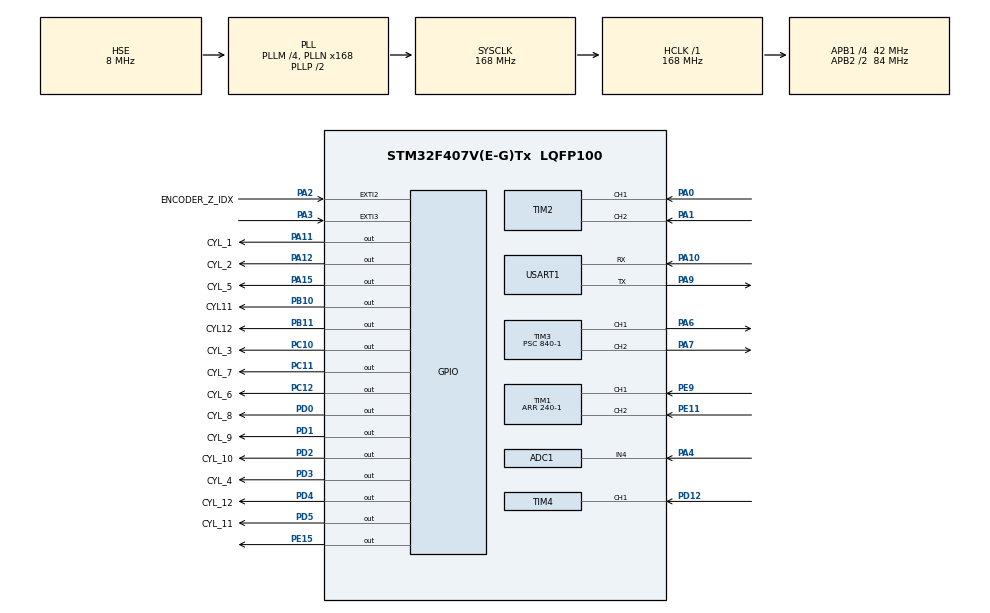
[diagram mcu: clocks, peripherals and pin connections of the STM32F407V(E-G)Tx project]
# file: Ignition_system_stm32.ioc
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ADC1.Channel-0\#ChannelRegularConversion=ADC_CHANNEL_4
ADC1.NbrOfConversionFlag=1
ADC1.Rank-0\#ChannelRegularConversion=1
ADC1.SamplingTime-0\#ChannelRegularConversion=ADC_SAMPLETIME_3CYCLES
ADC1.master=1
Mcu.Family=STM32F4
Mcu.Name=STM32F407V(E-G)Tx
Mcu.Package=LQFP100
NVIC.EXTI2_IRQn=true\:0\:0\:false\:false\:true\:true\:true\:true
NVIC.EXTI3_IRQn=true\:0\:0\:false\:false\:true\:true\:true\:true
NVIC.PriorityGroup=NVIC_PRIORITYGROUP_4
NVIC.TIM1_UP_TIM10_IRQn=true\:0\:0\:false\:false\:true\:true\:true\:true
NVIC.TIM4_IRQn=true\:0\:0\:false\:false\:true\:true\:true\:true
PA0-WKUP.Signal=S_TIM2_CH1_ETR
PA1.Signal=S_TIM2_CH2
PA10.Mode=Asynchronous
PA10.Signal=USART1_RX
PA11.GPIO_Label=CYL_1
PA11.GPIO_Speed=GPIO_SPEED_FREQ_VERY_HIGH
PA11.Signal=GPIO_Output
PA12.GPIO_Label=CYL_2
PA12.GPIO_Speed=GPIO_SPEED_FREQ_VERY_HIGH
PA12.Signal=GPIO_Output
PA13.Mode=Serial_Wire
PA13.Signal=SYS_JTMS-SWDIO
PA14.Mode=Serial_Wire
PA14.Signal=SYS_JTCK-SWCLK
PA15.GPIO_Label=CYL_5
PA15.GPIO_Speed=GPIO_SPEED_FREQ_VERY_HIGH
PA15.Signal=GPIO_Output
PA2.GPIO_Label=ENCODER_Z_IDX
PA2.GPIO_ModeDefaultEXTI=GPIO_MODE_IT_RISING
PA2.GPIO_PuPd=GPIO_NOPULL
PA2.Signal=GPXTI2
PA3.Signal=GPXTI3
PA4.Signal=ADCx_IN4
PA6.Signal=S_TIM3_CH1
PA7.Signal=S_TIM3_CH2
PA9.Mode=Asynchronous
PA9.Signal=USART1_TX
PB10.GPIO_Label=CYL11
PB10.GPIO_Speed=GPIO_SPEED_FREQ_VERY_HIGH
PB10.Signal=GPIO_Output
PB11.GPIO_Label=CYL12
PB11.GPIO_Speed=GPIO_SPEED_FREQ_VERY_HIGH
PB11.Signal=GPIO_Output
PC10.GPIO_Label=CYL_3
PC10.GPIO_Speed=GPIO_SPEED_FREQ_VERY_HIGH
PC10.Signal=GPIO_Output
PC11.GPIO_Label=CYL_7
PC11.GPIO_Speed=GPIO_SPEED_FREQ_VERY_HIGH
PC11.Signal=GPIO_Output
PC12.GPIO_Label=CYL_6
PC12.GPIO_Speed=GPIO_SPEED_FREQ_VERY_HIGH
PC12.Signal=GPIO_Output
PC14-OSC32_IN.Mode=LSE-External-Oscillator
PC14-OSC32_IN.Signal=RCC_OSC32_IN
PC15-OSC32_OUT.Mode=LSE-External-Oscillator
PC15-OSC32_OUT.Signal=RCC_OSC32_OUT
PD0.GPIO_Label=CYL_8
PD0.GPIO_Speed=GPIO_SPEED_FREQ_VERY_HIGH
PD0.Signal=GPIO_Output
PD1.GPIO_Label=CYL_9
PD1.GPIO_Speed=GPIO_SPEED_FREQ_VERY_HIGH
PD1.Signal=GPIO_Output
PD12.Signal=S_TIM4_CH1
PD2.GPIO_Label=CYL_10
PD2.GPIO_Speed=GPIO_SPEED_FREQ_VERY_HIGH
PD2.Signal=GPIO_Output
PD3.GPIO_Label=CYL_4
PD3.GPIO_Speed=GPIO_SPEED_FREQ_VERY_HIGH
PD3.Signal=GPIO_Output
PD4.GPIO_Label=CYL_12
PD4.GPIO_Speed=GPIO_SPEED_FREQ_VERY_HIGH
PD4.Signal=GPIO_Output
PD5.GPIO_Label=CYL_11
PD5.GPIO_Speed=GPIO_SPEED_FREQ_VERY_HIGH
PD5.Signal=GPIO_Output
PE11.Signal=S_TIM1_CH2
PE15.Signal=GPIO_Output
PE9.Signal=S_TIM1_CH1
PH0-OSC_IN.Mode=HSE-External-Oscillator
PH0-OSC_IN.Signal=RCC_OSC_IN
PH1-OSC_OUT.Mode=HSE-External-Oscillator
PH1-OSC_OUT.Signal=RCC_OSC_OUT
ProjectManager.HeapSize=0x200
ProjectManager.StackSize=0x400
ProjectManager.TargetToolchain=STM32CubeIDE
RCC.48MHZClocksFreq_Value=84000000
RCC.AHBFreq_Value=168000000
RCC.APB1CLKDivider=RCC_HCLK_DIV4
RCC.APB1Freq_Value=42000000
RCC.APB1TimFreq_Value=84000000
RCC.APB2CLKDivider=RCC_HCLK_DIV2
RCC.APB2Freq_Value=84000000
RCC.APB2TimFreq_Value=168000000
RCC.CortexFreq_Value=168000000
RCC.HCLKFreq_Value=168000000
RCC.HSE_VALUE=8000000
RCC.HSI_VALUE=16000000
RCC.PLLM=4
RCC.PLLN=168
RCC.PLLSourceVirtual=RCC_PLLSOURCE_HSE
RCC.SYSCLKFreq_VALUE=168000000
RCC.SYSCLKSource=RCC_SYSCLKSOURCE_PLLCLK
RCC.VCOOutputFreq_Value=336000000
SH.ADCx_IN4.0=ADC1_IN4,IN4
SH.S_TIM1_CH1.0=TIM1_CH1,Encoder_Interface
SH.S_TIM1_CH2.0=TIM1_CH2,Encoder_Interface
SH.S_TIM2_CH1_ETR.0=TIM2_CH1,Encoder_Interface
SH.S_TIM2_CH2.0=TIM2_CH2,Encoder_Interface
SH.S_TIM3_CH1.0=TIM3_CH1,PWM Generation1 CH1
SH.S_TIM3_CH2.0=TIM3_CH2,PWM Generation2 CH2
SH.S_TIM4_CH1.0=TIM4_CH1,Input_Capture1_from_TI1
TIM1.EncoderMode=TIM_ENCODERMODE_TI12
TIM1.IC1Polarity=TIM_ICPOLARITY_FALLING
TIM1.IC2Polarity=TIM_ICPOLARITY_FALLING
TIM1.Period=240-1
TIM2.EncoderMode=TIM_ENCODERMODE_TI12
TIM2.IC1Polarity=TIM_ICPOLARITY_FALLING
TIM2.IC2Polarity=TIM_ICPOLARITY_FALLING
TIM3.AutoReloadPreload=TIM_AUTORELOAD_PRELOAD_ENABLE
TIM3.Channel-PWM\ Generation1\ CH1=TIM_CHANNEL_1
TIM3.Channel-PWM\ Generation2\ CH2=TIM_CHANNEL_2
TIM3.Period=10000-1
TIM3.Prescaler=840-1
TIM4.Channel-Input_Capture1_from_TI1=TIM_CHANNEL_1
TIM4.ICPolarity_CH1=TIM_INPUTCHANNELPOLARITY_FALLING
TIM4.Prescaler=0
TIM5.Prescaler=84-1
USART1.VirtualMode=VM_ASYNC
VP_TIM3_VS_ClockSourceINT.Mode=Internal
VP_TIM4_VS_ClockSourceINT.Mode=Internal
VP_TIM5_VS_ClockSourceINT.Mode=Internal
VP_TIM8_VS_ClockSourceINT.Mode=Internal
board=custom

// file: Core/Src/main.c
/* USER CODE BEGIN Header */
/**
  ******************************************************************************
  * @file           : main.c
  * @brief          : Main program body
  ******************************************************************************
  * @attention
  *
  * Copyright (c) 2024 STMicroelectronics.
  * All rights reserved.
  *
  * This software is licensed under terms that can be found in the LICENSE file
  * in the root directory of this software component.
  * If no LICENSE file comes with this software, it is provided AS-IS.
  *
  ******************************************************************************
  */
/* USER CODE END Header */
#include "main.h"

/* USER CODE BEGIN Includes */
#include "submain.h"
#include "string.h"
/* USER CODE END Includes */

ADC_HandleTypeDef hadc1;

TIM_HandleTypeDef htim1;
TIM_HandleTypeDef htim2;
TIM_HandleTypeDef htim3;
TIM_HandleTypeDef htim4;
TIM_HandleTypeDef htim5;
TIM_HandleTypeDef htim8;

UART_HandleTypeDef huart1;

void SystemClock_Config(void);
static void MX_GPIO_Init(void);
static void MX_USART1_UART_Init(void);
static void MX_TIM2_Init(void);
static void MX_TIM1_Init(void);
static void MX_TIM4_Init(void);
static void MX_TIM3_Init(void);
static void MX_TIM5_Init(void);
static void MX_TIM8_Init(void);
static void MX_ADC1_Init(void);

int main(void)
{
  /* USER CODE BEGIN 1 */
/* uint8_t buf[12]; */
  /* USER CODE END 1 */

  /* MCU Configuration--------------------------------------------------------*/

  /* Reset of all peripherals, Initializes the Flash interface and the Systick. */
  HAL_Init();

  /* Configure the system clock */
  SystemClock_Config();

  /* Initialize all configured peripherals */
  MX_GPIO_Init();
  MX_USART1_UART_Init();
  MX_TIM2_Init();
  MX_TIM1_Init();
  MX_TIM4_Init();
  MX_TIM3_Init();
  MX_TIM5_Init();
  MX_TIM8_Init();
  MX_ADC1_Init();
  /* USER CODE BEGIN 2 */

  init();

  /* USER CODE END 2 */

  /* Infinite loop */
  /* USER CODE BEGIN WHILE */
  while (1)
  {
	  loop();

    /* USER CODE END WHILE */

  }
}

void SystemClock_Config(void)
{
  RCC_OscInitTypeDef RCC_OscInitStruct = {0};
  RCC_ClkInitTypeDef RCC_ClkInitStruct = {0};

  /** Configure the main internal regulator output voltage
  */
  __HAL_RCC_PWR_CLK_ENABLE();
  __HAL_PWR_VOLTAGESCALING_CONFIG(PWR_REGULATOR_VOLTAGE_SCALE1);

  /** Initializes the RCC Oscillators according to the specified parameters
  * in the RCC_OscInitTypeDef structure.
  */
  RCC_OscInitStruct.OscillatorType = RCC_OSCILLATORTYPE_HSE;
  RCC_OscInitStruct.HSEState = RCC_HSE_ON;
  RCC_OscInitStruct.PLL.PLLState = RCC_PLL_ON;
  RCC_OscInitStruct.PLL.PLLSource = RCC_PLLSOURCE_HSE;
  RCC_OscInitStruct.PLL.PLLM = 4;
  RCC_OscInitStruct.PLL.PLLN = 168;
  RCC_OscInitStruct.PLL.PLLP = RCC_PLLP_DIV2;
  RCC_OscInitStruct.PLL.PLLQ = 4;
  if (HAL_RCC_OscConfig(&RCC_OscInitStruct) != HAL_OK)
  {
    Error_Handler();
  }

  /** Initializes the CPU, AHB and APB buses clocks
  */
  RCC_ClkInitStruct.ClockType = RCC_CLOCKTYPE_HCLK|RCC_CLOCKTYPE_SYSCLK
                              |RCC_CLOCKTYPE_PCLK1|RCC_CLOCKTYPE_PCLK2;
  RCC_ClkInitStruct.SYSCLKSource = RCC_SYSCLKSOURCE_PLLCLK;
  RCC_ClkInitStruct.AHBCLKDivider = RCC_SYSCLK_DIV1;
  RCC_ClkInitStruct.APB1CLKDivider = RCC_HCLK_DIV4;
  RCC_ClkInitStruct.APB2CLKDivider = RCC_HCLK_DIV2;

  if (HAL_RCC_ClockConfig(&RCC_ClkInitStruct, FLASH_LATENCY_5) != HAL_OK)
  {
    Error_Handler();
  }
}

static void MX_ADC1_Init(void)
{

  ADC_ChannelConfTypeDef sConfig = {0};

  /** Configure the global features of the ADC (Clock, Resolution, Data Alignment and number of conversion)
  */
  hadc1.Instance = ADC1;
  hadc1.Init.ClockPrescaler = ADC_CLOCK_SYNC_PCLK_DIV4;
  hadc1.Init.Resolution = ADC_RESOLUTION_12B;
  hadc1.Init.ScanConvMode = DISABLE;
  hadc1.Init.ContinuousConvMode = DISABLE;
  hadc1.Init.DiscontinuousConvMode = DISABLE;
  hadc1.Init.ExternalTrigConvEdge = ADC_EXTERNALTRIGCONVEDGE_NONE;
  hadc1.Init.ExternalTrigConv = ADC_SOFTWARE_START;
  hadc1.Init.DataAlign = ADC_DATAALIGN_RIGHT;
  hadc1.Init.NbrOfConversion = 1;
  hadc1.Init.DMAContinuousRequests = DISABLE;
  hadc1.Init.EOCSelection = ADC_EOC_SINGLE_CONV;
  if (HAL_ADC_Init(&hadc1) != HAL_OK)
  {
    Error_Handler();
  }

  /** Configure for the selected ADC regular channel its corresponding rank in the sequencer and its sample time.
  */
  sConfig.Channel = ADC_CHANNEL_4;
  sConfig.Rank = 1;
  sConfig.SamplingTime = ADC_SAMPLETIME_3CYCLES;
  if (HAL_ADC_ConfigChannel(&hadc1, &sConfig) != HAL_OK)
  {
    Error_Handler();
  }

}

static void MX_TIM1_Init(void)
{

  TIM_Encoder_InitTypeDef sConfig = {0};
  TIM_MasterConfigTypeDef sMasterConfig = {0};

  htim1.Instance = TIM1;
  htim1.Init.Prescaler = 0;
  htim1.Init.CounterMode = TIM_COUNTERMODE_UP;
  htim1.Init.Period = 240-1;
  htim1.Init.ClockDivision = TIM_CLOCKDIVISION_DIV1;
  htim1.Init.RepetitionCounter = 0;
  htim1.Init.AutoReloadPreload = TIM_AUTORELOAD_PRELOAD_DISABLE;
  sConfig.EncoderMode = TIM_ENCODERMODE_TI12;
  sConfig.IC1Polarity = TIM_ICPOLARITY_FALLING;
  sConfig.IC1Selection = TIM_ICSELECTION_DIRECTTI;
  sConfig.IC1Prescaler = TIM_ICPSC_DIV1;
  sConfig.IC1Filter = 0;
  sConfig.IC2Polarity = TIM_ICPOLARITY_FALLING;
  sConfig.IC2Selection = TIM_ICSELECTION_DIRECTTI;
  sConfig.IC2Prescaler = TIM_ICPSC_DIV1;
  sConfig.IC2Filter = 0;
  if (HAL_TIM_Encoder_Init(&htim1, &sConfig) != HAL_OK)
  {
    Error_Handler();
  }
  sMasterConfig.MasterOutputTrigger = TIM_TRGO_RESET;
  sMasterConfig.MasterSlaveMode = TIM_MASTERSLAVEMODE_DISABLE;
  if (HAL_TIMEx_MasterConfigSynchronization(&htim1, &sMasterConfig) != HAL_OK)
  {
    Error_Handler();
  }

}

static void MX_TIM2_Init(void)
{

  TIM_Encoder_InitTypeDef sConfig = {0};
  TIM_MasterConfigTypeDef sMasterConfig = {0};

  htim2.Instance = TIM2;
  htim2.Init.Prescaler = 0;
  htim2.Init.CounterMode = TIM_COUNTERMODE_UP;
  htim2.Init.Period = 4294967295;
  htim2.Init.ClockDivision = TIM_CLOCKDIVISION_DIV1;
  htim2.Init.AutoReloadPreload = TIM_AUTORELOAD_PRELOAD_DISABLE;
  sConfig.EncoderMode = TIM_ENCODERMODE_TI12;
  sConfig.IC1Polarity = TIM_ICPOLARITY_FALLING;
  sConfig.IC1Selection = TIM_ICSELECTION_DIRECTTI;
  sConfig.IC1Prescaler = TIM_ICPSC_DIV1;
  sConfig.IC1Filter = 0;
  sConfig.IC2Polarity = TIM_ICPOLARITY_FALLING;
  sConfig.IC2Selection = TIM_ICSELECTION_DIRECTTI;
  sConfig.IC2Prescaler = TIM_ICPSC_DIV1;
  sConfig.IC2Filter = 0;
  if (HAL_TIM_Encoder_Init(&htim2, &sConfig) != HAL_OK)
  {
    Error_Handler();
  }
  sMasterConfig.MasterOutputTrigger = TIM_TRGO_RESET;
  sMasterConfig.MasterSlaveMode = TIM_MASTERSLAVEMODE_DISABLE;
  if (HAL_TIMEx_MasterConfigSynchronization(&htim2, &sMasterConfig) != HAL_OK)
  {
    Error_Handler();
  }

}

static void MX_TIM3_Init(void)
{

  TIM_ClockConfigTypeDef sClockSourceConfig = {0};
  TIM_MasterConfigTypeDef sMasterConfig = {0};
  TIM_OC_InitTypeDef sConfigOC = {0};

  htim3.Instance = TIM3;
  htim3.Init.Prescaler = 840-1;
  htim3.Init.CounterMode = TIM_COUNTERMODE_UP;
  htim3.Init.Period = 10000-1;
  htim3.Init.ClockDivision = TIM_CLOCKDIVISION_DIV1;
  htim3.Init.AutoReloadPreload = TIM_AUTORELOAD_PRELOAD_ENABLE;
  if (HAL_TIM_Base_Init(&htim3) != HAL_OK)
  {
    Error_Handler();
  }
  sClockSourceConfig.ClockSource = TIM_CLOCKSOURCE_INTERNAL;
  if (HAL_TIM_ConfigClockSource(&htim3, &sClockSourceConfig) != HAL_OK)
  {
    Error_Handler();
  }
  if (HAL_TIM_PWM_Init(&htim3) != HAL_OK)
  {
    Error_Handler();
  }
  sMasterConfig.MasterOutputTrigger = TIM_TRGO_RESET;
  sMasterConfig.MasterSlaveMode = TIM_MASTERSLAVEMODE_DISABLE;
  if (HAL_TIMEx_MasterConfigSynchronization(&htim3, &sMasterConfig) != HAL_OK)
  {
    Error_Handler();
  }
  sConfigOC.OCMode = TIM_OCMODE_PWM1;
  sConfigOC.Pulse = 0;
  sConfigOC.OCPolarity = TIM_OCPOLARITY_HIGH;
  sConfigOC.OCFastMode = TIM_OCFAST_DISABLE;
  if (HAL_TIM_PWM_ConfigChannel(&htim3, &sConfigOC, TIM_CHANNEL_1) != HAL_OK)
  {
    Error_Handler();
  }
  if (HAL_TIM_PWM_ConfigChannel(&htim3, &sConfigOC, TIM_CHANNEL_2) != HAL_OK)
  {
    Error_Handler();
  }
  HAL_TIM_MspPostInit(&htim3);

}

static void MX_TIM4_Init(void)
{

  TIM_ClockConfigTypeDef sClockSourceConfig = {0};
  TIM_MasterConfigTypeDef sMasterConfig = {0};
  TIM_IC_InitTypeDef sConfigIC = {0};

  htim4.Instance = TIM4;
  htim4.Init.Prescaler = 0;
  htim4.Init.CounterMode = TIM_COUNTERMODE_UP;
  htim4.Init.Period = 65535;
  htim4.Init.ClockDivision = TIM_CLOCKDIVISION_DIV1;
  htim4.Init.AutoReloadPreload = TIM_AUTORELOAD_PRELOAD_DISABLE;
  if (HAL_TIM_Base_Init(&htim4) != HAL_OK)
  {
    Error_Handler();
  }
  sClockSourceConfig.ClockSource = TIM_CLOCKSOURCE_INTERNAL;
  if (HAL_TIM_ConfigClockSource(&htim4, &sClockSourceConfig) != HAL_OK)
  {
    Error_Handler();
  }
  if (HAL_TIM_IC_Init(&htim4) != HAL_OK)
  {
    Error_Handler();
  }
  sMasterConfig.MasterOutputTrigger = TIM_TRGO_RESET;
  sMasterConfig.MasterSlaveMode = TIM_MASTERSLAVEMODE_DISABLE;
  if (HAL_TIMEx_MasterConfigSynchronization(&htim4, &sMasterConfig) != HAL_OK)
  {
    Error_Handler();
  }
  sConfigIC.ICPolarity = TIM_INPUTCHANNELPOLARITY_FALLING;
  sConfigIC.ICSelection = TIM_ICSELECTION_DIRECTTI;
  sConfigIC.ICPrescaler = TIM_ICPSC_DIV1;
  sConfigIC.ICFilter = 0;
  if (HAL_TIM_IC_ConfigChannel(&htim4, &sConfigIC, TIM_CHANNEL_1) != HAL_OK)
  {
    Error_Handler();
  }

}

static void MX_TIM5_Init(void)
{

  TIM_ClockConfigTypeDef sClockSourceConfig = {0};
  TIM_MasterConfigTypeDef sMasterConfig = {0};

  htim5.Instance = TIM5;
  htim5.Init.Prescaler = 84-1;
  htim5.Init.CounterMode = TIM_COUNTERMODE_UP;
  htim5.Init.Period = 4294967295;
  htim5.Init.ClockDivision = TIM_CLOCKDIVISION_DIV1;
  htim5.Init.AutoReloadPreload = TIM_AUTORELOAD_PRELOAD_DISABLE;
  if (HAL_TIM_Base_Init(&htim5) != HAL_OK)
  {
    Error_Handler();
  }
  sClockSourceConfig.ClockSource = TIM_CLOCKSOURCE_INTERNAL;
  if (HAL_TIM_ConfigClockSource(&htim5, &sClockSourceConfig) != HAL_OK)
  {
    Error_Handler();
  }
  sMasterConfig.MasterOutputTrigger = TIM_TRGO_RESET;
  sMasterConfig.MasterSlaveMode = TIM_MASTERSLAVEMODE_DISABLE;
  if (HAL_TIMEx_MasterConfigSynchronization(&htim5, &sMasterConfig) != HAL_OK)
  {
    Error_Handler();
  }

}

static void MX_TIM8_Init(void)
{

  TIM_ClockConfigTypeDef sClockSourceConfig = {0};
  TIM_MasterConfigTypeDef sMasterConfig = {0};

  htim8.Instance = TIM8;
  htim8.Init.Prescaler = 0;
  htim8.Init.CounterMode = TIM_COUNTERMODE_UP;
  htim8.Init.Period = 65535;
  htim8.Init.ClockDivision = TIM_CLOCKDIVISION_DIV1;
  htim8.Init.RepetitionCounter = 0;
  htim8.Init.AutoReloadPreload = TIM_AUTORELOAD_PRELOAD_DISABLE;
  if (HAL_TIM_Base_Init(&htim8) != HAL_OK)
  {
    Error_Handler();
  }
  sClockSourceConfig.ClockSource = TIM_CLOCKSOURCE_INTERNAL;
  if (HAL_TIM_ConfigClockSource(&htim8, &sClockSourceConfig) != HAL_OK)
  {
    Error_Handler();
  }
  sMasterConfig.MasterOutputTrigger = TIM_TRGO_RESET;
  sMasterConfig.MasterSlaveMode = TIM_MASTERSLAVEMODE_DISABLE;
  if (HAL_TIMEx_MasterConfigSynchronization(&htim8, &sMasterConfig) != HAL_OK)
  {
    Error_Handler();
  }

}

static void MX_USART1_UART_Init(void)
{

  huart1.Instance = USART1;
  huart1.Init.BaudRate = 115200;
  huart1.Init.WordLength = UART_WORDLENGTH_8B;
  huart1.Init.StopBits = UART_STOPBITS_1;
  huart1.Init.Parity = UART_PARITY_NONE;
  huart1.Init.Mode = UART_MODE_TX_RX;
  huart1.Init.HwFlowCtl = UART_HWCONTROL_NONE;
  huart1.Init.OverSampling = UART_OVERSAMPLING_16;
  if (HAL_UART_Init(&huart1) != HAL_OK)
  {
    Error_Handler();
  }

}

static void MX_GPIO_Init(void)
{
  GPIO_InitTypeDef GPIO_InitStruct = {0};

  /* GPIO Ports Clock Enable */
  __HAL_RCC_GPIOC_CLK_ENABLE();
  __HAL_RCC_GPIOH_CLK_ENABLE();
  __HAL_RCC_GPIOA_CLK_ENABLE();
  __HAL_RCC_GPIOE_CLK_ENABLE();
  __HAL_RCC_GPIOB_CLK_ENABLE();
  __HAL_RCC_GPIOD_CLK_ENABLE();

  /*Configure GPIO pin Output Level */
  HAL_GPIO_WritePin(GPIOE, GPIO_PIN_15, GPIO_PIN_RESET);

  /*Configure GPIO pin Output Level */
  HAL_GPIO_WritePin(GPIOB, CYL11_Pin|CYL12_Pin, GPIO_PIN_RESET);

  /*Configure GPIO pin Output Level */
  HAL_GPIO_WritePin(GPIOA, CYL_1_Pin|CYL_2_Pin|CYL_5_Pin, GPIO_PIN_RESET);

  /*Configure GPIO pin Output Level */
  HAL_GPIO_WritePin(GPIOC, CYL_3_Pin|CYL_7_Pin|CYL_6_Pin, GPIO_PIN_RESET);

  /*Configure GPIO pin Output Level */
  HAL_GPIO_WritePin(GPIOD, CYL_8_Pin|CYL_9_Pin|CYL_10_Pin|CYL_4_Pin
                          |CYL_12_Pin|CYL_11_Pin, GPIO_PIN_RESET);

  /*Configure GPIO pins : ENCODER_Z_IDX_Pin PA3 */
  GPIO_InitStruct.Pin = ENCODER_Z_IDX_Pin|GPIO_PIN_3;
  GPIO_InitStruct.Mode = GPIO_MODE_IT_RISING;
  GPIO_InitStruct.Pull = GPIO_NOPULL;
  HAL_GPIO_Init(GPIOA, &GPIO_InitStruct);

  /*Configure GPIO pin : PE15 */
  GPIO_InitStruct.Pin = GPIO_PIN_15;
  GPIO_InitStruct.Mode = GPIO_MODE_OUTPUT_PP;
  GPIO_InitStruct.Pull = GPIO_NOPULL;
  GPIO_InitStruct.Speed = GPIO_SPEED_FREQ_LOW;
  HAL_GPIO_Init(GPIOE, &GPIO_InitStruct);

  /*Configure GPIO pins : CYL11_Pin CYL12_Pin */
  GPIO_InitStruct.Pin = CYL11_Pin|CYL12_Pin;
  GPIO_InitStruct.Mode = GPIO_MODE_OUTPUT_PP;
  GPIO_InitStruct.Pull = GPIO_NOPULL;
  GPIO_InitStruct.Speed = GPIO_SPEED_FREQ_VERY_HIGH;
  HAL_GPIO_Init(GPIOB, &GPIO_InitStruct);

  /*Configure GPIO pins : CYL_1_Pin CYL_2_Pin CYL_5_Pin */
  GPIO_InitStruct.Pin = CYL_1_Pin|CYL_2_Pin|CYL_5_Pin;
  GPIO_InitStruct.Mode = GPIO_MODE_OUTPUT_PP;
  GPIO_InitStruct.Pull = GPIO_NOPULL;
  GPIO_InitStruct.Speed = GPIO_SPEED_FREQ_VERY_HIGH;
  HAL_GPIO_Init(GPIOA, &GPIO_InitStruct);

  /*Configure GPIO pins : CYL_3_Pin CYL_7_Pin CYL_6_Pin */
  GPIO_InitStruct.Pin = CYL_3_Pin|CYL_7_Pin|CYL_6_Pin;
  GPIO_InitStruct.Mode = GPIO_MODE_OUTPUT_PP;
  GPIO_InitStruct.Pull = GPIO_NOPULL;
  GPIO_InitStruct.Speed = GPIO_SPEED_FREQ_VERY_HIGH;
  HAL_GPIO_Init(GPIOC, &GPIO_InitStruct);

  /*Configure GPIO pins : CYL_8_Pin CYL_9_Pin CYL_10_Pin CYL_4_Pin
                           CYL_12_Pin CYL_11_Pin */
  GPIO_InitStruct.Pin = CYL_8_Pin|CYL_9_Pin|CYL_10_Pin|CYL_4_Pin
                          |CYL_12_Pin|CYL_11_Pin;
  GPIO_InitStruct.Mode = GPIO_MODE_OUTPUT_PP;
  GPIO_InitStruct.Pull = GPIO_NOPULL;
  GPIO_InitStruct.Speed = GPIO_SPEED_FREQ_VERY_HIGH;
  HAL_GPIO_Init(GPIOD, &GPIO_InitStruct);

  /* EXTI interrupt init*/
  HAL_NVIC_SetPriority(EXTI2_IRQn, 0, 0);
  HAL_NVIC_EnableIRQ(EXTI2_IRQn);

  HAL_NVIC_SetPriority(EXTI3_IRQn, 0, 0);
  HAL_NVIC_EnableIRQ(EXTI3_IRQn);

}

void Error_Handler(void)
{
  __disable_irq();
  while (1)
  {
  }
}
